# MIMXRT1064 register map
Vendor: nxp.com; File version: 1.0
CPU: CM7 r0p1, little endian, MPU, FPU, VTOR, 4 interrupt priority bits
Registers are 32-bit, read-write, reset 0x0 unless marked. A register's access mark holds for its fields unless they carry their own. Offsets are from the block's base; [hi:lo] are bit positions; {n}, {i} and the like mark numbered series; 'fields as' and 'values as' point back to an identical list.

## USB1 — USB
Base 0x402E0000; register names take the prefix USB_
Same registers: USB2 0x402E0200
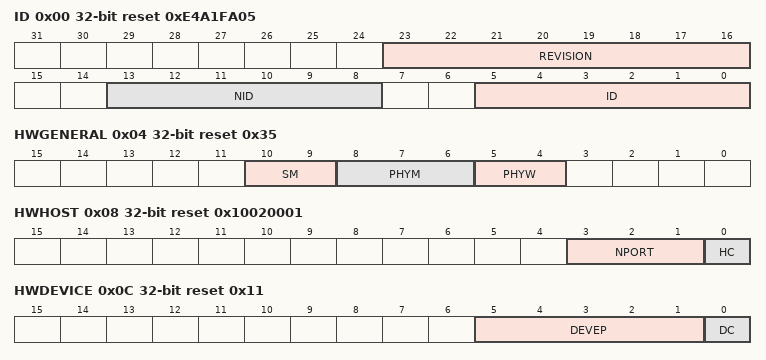
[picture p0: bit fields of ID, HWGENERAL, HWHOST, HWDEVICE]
0x00 ID ro reset 0xE4A1FA05 — Identification register
  [23:16] REVISION — Revision number of the controller core.
  [13:8] NID — Complement version of ID
  [5:0] ID — Configuration number
0x04 HWGENERAL ro reset 0x35 — Hardware General
  [10:9] SM — Serial interface mode capability
    0=No Serial Engine, always use parallel signalling; 1=Serial Engine present, always use serial signalling for FS/LS; 2=Software programmable - Reset to use parallel signalling for FS/LS; 3=Software programmable - Reset to use serial signalling for FS/LS
  [8:6] PHYM — Transciever type
    0=UTMI/UMTI+; 1=ULPI DDR; 2=ULPI; 3=Serial Only; 4=Software programmable - reset to UTMI/UTMI+; 5=Software programmable - reset to ULPI DDR; 6=Software programmable - reset to ULPI; 7=Software programmable - reset to Serial
  [5:4] PHYW — Data width of the transciever connected to the controller core. PHYW bit reset value is
    0=8 bit wide data bus Software non-programmable; 1=16 bit wide data bus Software non-programmable; 2=Reset to 8 bit wide data bus Software programmable; 3=Reset to 16 bit wide data bus Software programmable
0x08 HWHOST ro reset 0x10020001 — Host Hardware Parameters
  [3:1] NPORT — The Nmber of downstream ports supported by the host controller is (NPORT+1)
  [0] HC — Host Capable. Indicating whether host operation mode is supported or not.
    0=Not supported; 1=Supported
0x0C HWDEVICE ro reset 0x11 — Device Hardware Parameters
  [5:1] DEVEP — Device Endpoint Number
  [0] DC — Device Capable. Indicating whether device operation mode is supported or not.
    0=Not supported; 1=Supported
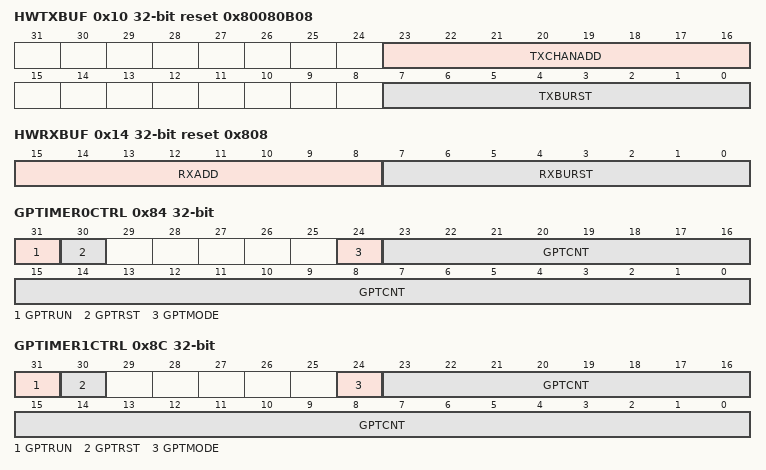
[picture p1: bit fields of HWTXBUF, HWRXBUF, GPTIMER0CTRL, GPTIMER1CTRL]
0x10 HWTXBUF ro reset 0x80080B08 — TX Buffer Hardware Parameters
  [23:16] TXCHANADD — TX FIFO Buffer size is: (2^TXCHANADD) * 4 Bytes
  [7:0] TXBURST — Default burst size for memory to TX buffer transfer
0x14 HWRXBUF ro reset 0x808 — RX Buffer Hardware Parameters
  [15:8] RXADD — Buffer total size for all receive endpoints is (2^RXADD)
  [7:0] RXBURST — Default burst size for memory to RX buffer transfer
0x80 GPTIMER0LD — General Purpose Timer #0 Load
  [23:0] GPTLD — General Purpose Timer Load Value These bit fields are loaded to GPTCNT bits when GPTRST bit is set '1b'
0x84 GPTIMER0CTRL — General Purpose Timer #0 Controller
  [31] GPTRUN — General Purpose Timer Run GPTCNT bits are not effected when setting or clearing this bit.
    0=Stop counting; 1=Run
  [30] GPTRST — General Purpose Timer Reset
    0=No action; 1=Load counter value from GPTLD bits in n_GPTIMER0LD
  [24] GPTMODE — General Purpose Timer Mode In one shot mode, the timer will count down to zero, generate an interrupt, and stop until the counter is reset by software; In repeat mode, the timer will count down to zero, generate an interrupt and automatically reload the counter value from GPTLD bits to start again
    0=One Shot Mode; 1=Repeat Mode
  [23:0] GPTCNT — General Purpose Timer Counter. This field is the count value of the countdown timer.
0x88 GPTIMER1LD — General Purpose Timer #1 Load
  fields as GPTIMER0LD
0x8C GPTIMER1CTRL — General Purpose Timer #1 Controller
  [31] GPTRUN — General Purpose Timer Run GPTCNT bits are not effected when setting or clearing this bit.
    0=Stop counting; 1=Run
  [30] GPTRST — General Purpose Timer Reset
    0=No action; 1=Load counter value from GPTLD bits in USB_n_GPTIMER0LD
  [24] GPTMODE — General Purpose Timer Mode In one shot mode, the timer will count down to zero, generate an interrupt, and stop until the counter is reset by software
    0=One Shot Mode; 1=Repeat Mode
  [23:0] GPTCNT — General Purpose Timer Counter. This field is the count value of the countdown timer.
0x90 SBUSCFG reset 0x2 — System Bus Config
  [2:0] AHBBRST — AHB master interface Burst configuration These bits control AHB master transfer type sequence (or priority)
    0=Incremental burst of unspecified length only; 1=INCR4 burst, then single transfer; 2=INCR8 burst, INCR4 burst, then single transfer; 3=INCR16 burst, INCR8 burst, INCR4 burst, then single transfer; 5=INCR4 burst, then incremental burst of unspecified length; 6=INCR8 burst, INCR4 burst, then incremental burst of unspecified length; 7=INCR16 burst, INCR8 burst, INCR4 burst, then incremental burst of unspecified length
0x100 CAPLENGTH 8-bit ro reset 0x40 — Capability Registers Length
  [7:0] CAPLENGTH — These bits are used as an offset to add to register base to find the beginning of the Operational Register
0x102 HCIVERSION 16-bit ro reset 0x100 — Host Controller Interface Version
  [15:0] HCIVERSION — Host Controller Interface Version Number Default value is '10h', which means EHCI rev1.0.
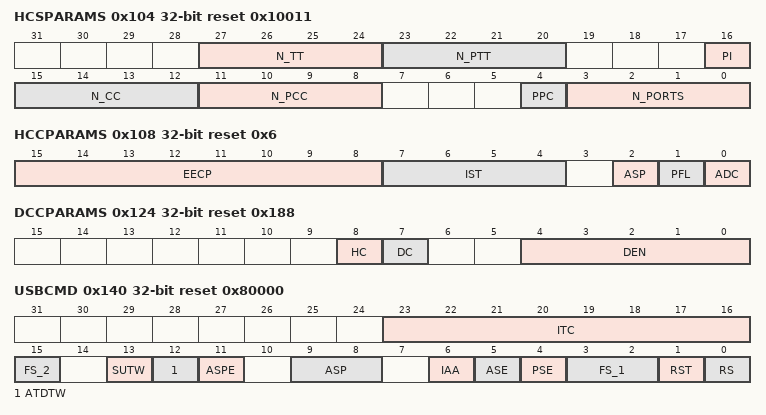
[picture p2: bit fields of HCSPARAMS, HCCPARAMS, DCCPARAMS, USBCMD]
0x104 HCSPARAMS ro reset 0x10011 — Host Controller Structural Parameters
  [27:24] N_TT — Number of Transaction Translators (N_TT)
  [23:20] N_PTT — Number of Ports per Transaction Translator (N_PTT)
  [16] PI — Port Indicators (P INDICATOR) This bit indicates whether the ports support port indicator control
  [15:12] N_CC — Number of Companion Controller (N_CC)
    0=There is no internal Companion Controller and port-ownership hand-off is not supported; 1=There are internal companion controller(s) and port-ownership hand-offs is supported
  [11:8] N_PCC — Number of Ports per Companion Controller This field indicates the number of ports supported per internal Companion Controller
  [4] PPC — Port Power Control This field indicates whether the host controller implementation includes port power control
  [3:0] N_PORTS — Number of downstream ports
0x108 HCCPARAMS ro reset 0x6 — Host Controller Capability Parameters
  [15:8] EECP — EHCI Extended Capabilities Pointer
  [7:4] IST — Isochronous Scheduling Threshold
  [2] ASP — Asynchronous Schedule Park Capability If this bit is set to a one, then the host controller supports the park feature for high-speed queue heads in the Asynchronous Schedule
  [1] PFL — Programmable Frame List Flag If this bit is set to zero, then the system software must use a frame list length of 1024 elements with this host controller
  [0] ADC — 64-bit Addressing Capability This bit is set '0b' in all controller core, no 64-bit addressing capability is supported
0x120 DCIVERSION 16-bit ro reset 0x1 — Device Controller Interface Version
  [15:0] DCIVERSION — Device Controller Interface Version Number Default value is '01h', which means rev0.1.
0x124 DCCPARAMS ro reset 0x188 — Device Controller Capability Parameters
  [8] HC — Host Capable When this bit is 1, this controller is capable of operating as an EHCI compatible USB 2
  [7] DC — Device Capable When this bit is 1, this controller is capable of operating as a USB 2.0 device.
  [4:0] DEN — Device Endpoint Number This field indicates the number of endpoints built into the device controller
0x140 USBCMD reset 0x80000 — USB Command Register
  [23:16] ITC — Interrupt Threshold Control -Read/Write
    0=Immediate (no threshold); 1=1 micro-frame; 2=2 micro-frames; 4=4 micro-frames; 8=8 micro-frames; 16=16 micro-frames; 32=32 micro-frames; 64=64 micro-frames
  [15] FS_2 — See also bits 3-2 Frame List Size - (Read/Write or Read Only)
    0=1024 elements (4096 bytes) Default value; 1=512 elements (2048 bytes)
  [13] SUTW — Setup TripWire - Read/Write
  [12] ATDTW — Add dTD TripWire - Read/Write
  [11] ASPE — Asynchronous Schedule Park Mode Enable - Read/Write
  [9:8] ASP — Asynchronous Schedule Park Mode Count - Read/Write
  [6] IAA — Interrupt on Async Advance Doorbell - Read/Write
  [5] ASE — Asynchronous Schedule Enable - Read/Write
    0=Do not process the Asynchronous Schedule; 1=Use the ASYNCLISTADDR register to access the Asynchronous Schedule
  [4] PSE — Periodic Schedule Enable- Read/Write
    0=Do not process the Periodic Schedule; 1=Use the PERIODICLISTBASE register to access the Periodic Schedule
  [3:2] FS_1 — See description at bit 15
  [1] RST — Controller Reset (RESET) - Read/Write
  [0] RS — Run/Stop (RS) - Read/Write
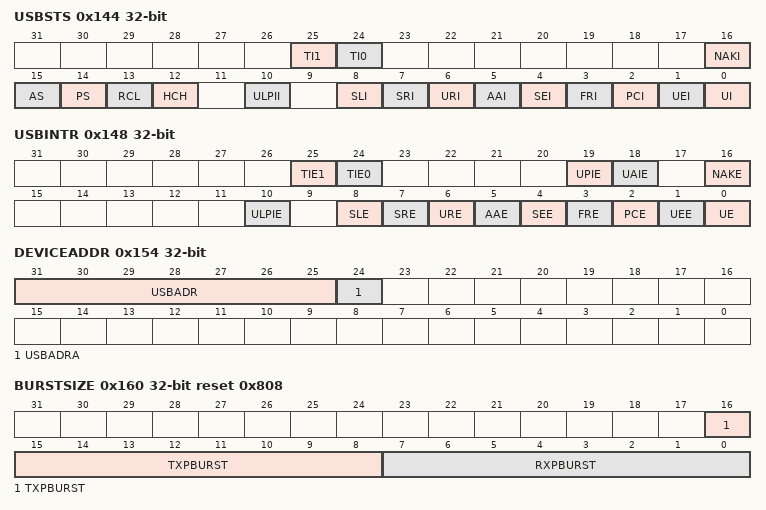
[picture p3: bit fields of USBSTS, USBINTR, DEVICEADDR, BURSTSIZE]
0x144 USBSTS — USB Status Register
  [25] TI1 — General Purpose Timer Interrupt 1(GPTINT1)--R/WC
  [24] TI0 — General Purpose Timer Interrupt 0(GPTINT0)--R/WC
  [16] NAKI ro — NAK Interrupt Bit--RO
  [15] AS — Asynchronous Schedule Status - Read Only
  [14] PS — Periodic Schedule Status - Read Only
  [13] RCL — Reclamation - Read Only
  [12] HCH — HCHaIted - Read Only
  [10] ULPII — ULPI Interrupt - R/WC
  [8] SLI — DCSuspend - R/WC
  [7] SRI — SOF Received - R/WC
  [6] URI — USB Reset Received - R/WC
  [5] AAI — Interrupt on Async Advance - R/WC
  [4] SEI — System Error- R/WC
  [3] FRI — Frame List Rollover - R/WC
  [2] PCI — Port Change Detect - R/WC
  [1] UEI — USB Error Interrupt (USBERRINT) - R/WC
  [0] UI — USB Interrupt (USBINT) - R/WC
0x148 USBINTR — Interrupt Enable Register
  [25] TIE1 — General Purpose Timer #1 Interrupt Enable When this bit is one and the TI1 bit in n_USBSTS register is a one the controller will issue an interrupt
  [24] TIE0 — General Purpose Timer #0 Interrupt Enable When this bit is one and the TI0 bit in n_USBSTS register is a one the controller will issue an interrupt
  [19] UPIE — USB Host Periodic Interrupt Enable When this bit is one, and the UPI bit in the n_USBSTS register is one, host controller will issue an interrupt at the next interrupt threshold
  [18] UAIE — USB Host Asynchronous Interrupt Enable When this bit is one, and the UAI bit in the n_USBSTS register is one, host controller will issue an interrupt at the next interrupt threshold
  [16] NAKE — NAK Interrupt Enable When this bit is one and the NAKI bit in n_USBSTS register is a one the controller will issue an interrupt
  [10] ULPIE — ULPI Interrupt Enable When this bit is one and the UPLII bit in n_USBSTS register is a one the controller will issue an interrupt
  [8] SLE — Sleep Interrupt Enable When this bit is one and the SLI bit in n_n_USBSTS register is a one the controller will issue an interrupt
  [7] SRE — SOF Received Interrupt Enable When this bit is one and the SRI bit in n_USBSTS register is a one the controller will issue an interrupt
  [6] URE — USB Reset Interrupt Enable When this bit is one and the URI bit in n_USBSTS register is a one the controller will issue an interrupt
  [5] AAE — Async Advance Interrupt Enable When this bit is one and the AAI bit in n_USBSTS register is a one the controller will issue an interrupt
  [4] SEE — System Error Interrupt Enable When this bit is one and the SEI bit in n_USBSTS register is a one the controller will issue an interrupt
  [3] FRE — Frame List Rollover Interrupt Enable When this bit is one and the FRI bit in n_USBSTS register is a one the controller will issue an interrupt
  [2] PCE — Port Change Detect Interrupt Enable When this bit is one and the PCI bit in n_USBSTS register is a one the controller will issue an interrupt
  [1] UEE — USB Error Interrupt Enable When this bit is one and the UEI bit in n_USBSTS register is a one the controller will issue an interrupt
  [0] UE — USB Interrupt Enable When this bit is one and the UI bit in n_USBSTS register is a one the controller will issue an interrupt
0x14C FRINDEX — USB Frame Index
  [13:0] FRINDEX — Frame Index
    0=(1024) 12; 1=(512) 11; 2=(256) 10; 3=(128) 9; 4=(64) 8; 5=(32) 7; 6=(16) 6; 7=(8) 5
0x154 DEVICEADDR (DEVICEADDR_PERIODICLISTBASE view) — Device Address
  [31:25] USBADR — Device Address. These bits correspond to the USB device address
  [24] USBADRA — Device Address Advance
0x154 PERIODICLISTBASE (DEVICEADDR_PERIODICLISTBASE view) — Frame List Base Address
  [31:12] BASEADR — Base Address (Low)
0x158 ASYNCLISTADDR (ASYNCLISTADDR_ENDPTLISTADDR view) — Next Asynch. Address
  [31:5] ASYBASE — Link Pointer Low (LPL)
0x158 ENDPTLISTADDR (ASYNCLISTADDR_ENDPTLISTADDR view) — Endpoint List Address
  [31:11] EPBASE — Endpoint List Pointer(Low)
0x160 BURSTSIZE reset 0x808 — Programmable Burst Size
  [16:8] TXPBURST — Programmable TX Burst Size
  [7:0] RXPBURST — Programmable RX Burst Size
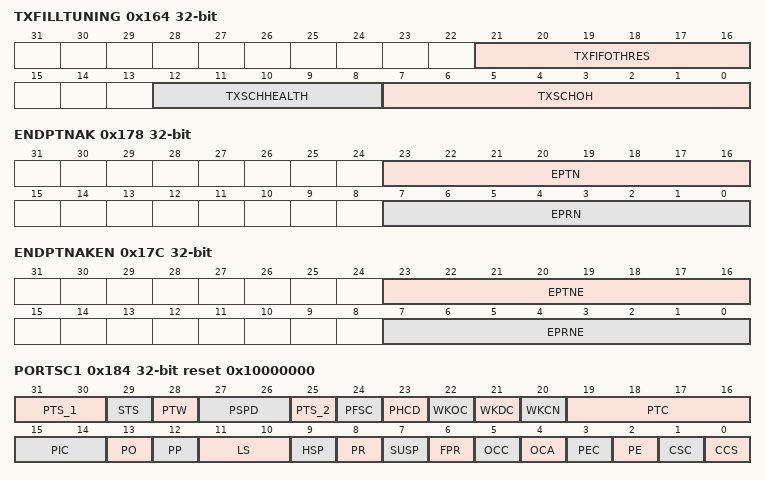
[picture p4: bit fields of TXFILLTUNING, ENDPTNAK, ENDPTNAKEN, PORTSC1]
0x164 TXFILLTUNING — TX FIFO Fill Tuning
  [21:16] TXFIFOTHRES — FIFO Burst Threshold
  [12:8] TXSCHHEALTH — Scheduler Health Counter
  [7:0] TXSCHOH — Scheduler Overhead
0x178 ENDPTNAK — Endpoint NAK
  [23:16] EPTN — TX Endpoint NAK - R/WC
  [7:0] EPRN — RX Endpoint NAK - R/WC
0x17C ENDPTNAKEN — Endpoint NAK Enable
  [23:16] EPTNE — TX Endpoint NAK Enable - R/W
  [7:0] EPRNE — RX Endpoint NAK Enable - R/W
0x180 CONFIGFLAG ro reset 0x1 — Configure Flag Register
  [0] CF — Configure Flag Host software sets this bit as the last action in its process of configuring the Host Controller
    0=Port routing control logic default-routes each port to an implementation dependent classic host controller; 1=Port routing control logic default-routes all ports to this host controller
0x184 PORTSC1 reset 0x10000000 — Port Status & Control
  [31:30] PTS_1 — All USB port interface modes are listed in this field description, but not all are supported
  [29] STS — Serial Transceiver Select 1 Serial Interface Engine is selected 0 Parallel Interface signals is selected Serial Interface Engine can be used in combination with UTMI+/ULPI physical interface to provide FS/LS signaling instead of the parallel interface signals
  [28] PTW — Parallel Transceiver Width This bit has no effect if serial interface engine is used
    0=Select the 8-bit UTMI interface [60MHz]; 1=Select the 16-bit UTMI interface [30MHz]
  [27:26] PSPD — Port Speed - Read Only. This register field indicates the speed at which the port is operating.
    0=Full Speed; 1=Low Speed; 2=High Speed; 3=Undefined
  [25] PTS_2 — See description at bits 31-30
  [24] PFSC — Port Force Full Speed Connect - Read/Write
    0=Normal operation; 1=Forced to full speed
  [23] PHCD — PHY Low Power Suspend - Clock Disable (PLPSCD) - Read/Write
    0=Enable PHY clock; 1=Disable PHY clock
  [22] WKOC — Wake on Over-current Enable (WKOC_E) - Read/Write
  [21] WKDC — Wake on Disconnect Enable (WKDSCNNT_E) - Read/Write
  [20] WKCN — Wake on Connect Enable (WKCNNT_E) - Read/Write
  [19:16] PTC — Port Test Control - Read/Write
    0=TEST_MODE_DISABLE; 1=J_STATE; 2=K_STATE; 3=SE0 (host) / NAK (device); 4=Packet; 5=FORCE_ENABLE_HS; 6=FORCE_ENABLE_FS; 7=FORCE_ENABLE_LS
  [15:14] PIC — Port Indicator Control - Read/Write
    0=Port indicators are off; 1=Amber; 2=Green; 3=Undefined
  [13] PO — Port Owner-Read/Write
  [12] PP — Port Power (PP)-Read/Write or Read Only
  [11:10] LS — Line Status-Read Only
    0=SE0; 1=K-state; 2=J-state; 3=Undefined
  [9] HSP ro — High-Speed Port - Read Only
  [8] PR — Port Reset - Read/Write or Read Only
  [7] SUSP — Suspend - Read/Write or Read Only
  [6] FPR — Force Port Resume -Read/Write
  [5] OCC — Over-current Change-R/WC
  [4] OCA ro — Over-current Active-Read Only
    0=This port does not have an over-current condition; 1=This port currently has an over-current condition
  [3] PEC — Port Enable/Disable Change-R/WC
  [2] PE — Port Enabled/Disabled-Read/Write
  [1] CSC — Connect Status Change-R/WC
  [0] CCS ro — Current Connect Status-Read Only
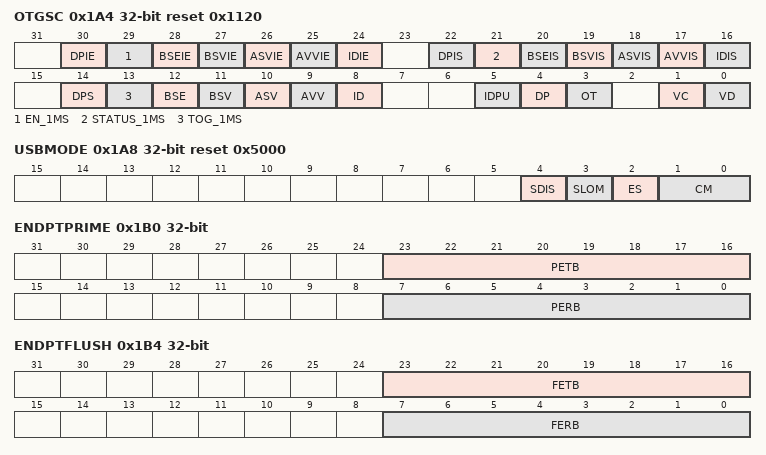
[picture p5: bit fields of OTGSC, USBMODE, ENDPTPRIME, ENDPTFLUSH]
0x1A4 OTGSC reset 0x1120 — On-The-Go Status & control
  [30] DPIE — Data Pulse Interrupt Enable
  [29] EN_1MS — 1 millisecond timer Interrupt Enable - Read/Write
  [28] BSEIE — B Session End Interrupt Enable - Read/Write. Setting this bit enables the B session end interrupt.
  [27] BSVIE — B Session Valid Interrupt Enable - Read/Write
  [26] ASVIE — A Session Valid Interrupt Enable - Read/Write
  [25] AVVIE — A VBus Valid Interrupt Enable - Read/Write. Setting this bit enables the A VBus valid interrupt.
  [24] IDIE — USB ID Interrupt Enable - Read/Write. Setting this bit enables the USB ID interrupt.
  [22] DPIS — Data Pulse Interrupt Status - Read/Write to Clear
  [21] STATUS_1MS — 1 millisecond timer Interrupt Status - Read/Write to Clear
  [20] BSEIS — B Session End Interrupt Status - Read/Write to Clear
  [19] BSVIS — B Session Valid Interrupt Status - Read/Write to Clear
  [18] ASVIS — A Session Valid Interrupt Status - Read/Write to Clear
  [17] AVVIS — A VBus Valid Interrupt Status - Read/Write to Clear
  [16] IDIS — USB ID Interrupt Status - Read/Write
  [14] DPS ro — Data Bus Pulsing Status - Read Only
  [13] TOG_1MS ro — 1 millisecond timer toggle - Read Only. This bit toggles once per millisecond.
  [12] BSE ro — B Session End - Read Only. Indicates VBus is below the B session end threshold.
  [11] BSV ro — B Session Valid - Read Only. Indicates VBus is above the B session valid threshold.
  [10] ASV ro — A Session Valid - Read Only. Indicates VBus is above the A session valid threshold.
  [9] AVV ro — A VBus Valid - Read Only. Indicates VBus is above the A VBus valid threshold.
  [8] ID ro — USB ID - Read Only. 0 = A device, 1 = B device
  [5] IDPU — ID Pullup - Read/Write This bit provide control over the ID pull-up resistor; 0 = off, 1 = on [default]
  [4] DP — Data Pulsing - Read/Write
  [3] OT — OTG Termination - Read/Write
  [1] VC — VBUS Charge - Read/Write
  [0] VD — VBUS_Discharge - Read/Write. Setting this bit causes VBus to discharge through a resistor.
0x1A8 USBMODE reset 0x5000 — USB Device Mode
  [4] SDIS — Stream Disable Mode
  [3] SLOM — Setup Lockout Mode
    0=Setup Lockouts On (default);; 1=Setup Lockouts Off (DCD requires use of Setup Data Buffer Tripwire in USBCMDUSB Command Register 
  [2] ES — Endian Select - Read/Write
    0=Little Endian [Default]; 1=Big Endian
  [1:0] CM — Controller Mode - R/WO
    0=Idle [Default for combination host/device]; 2=Device Controller [Default for device only controller]; 3=Host Controller [Default for host only controller]
0x1AC ENDPTSETUPSTAT — Endpoint Setup Status
  [15:0] ENDPTSETUPSTAT — Setup Endpoint Status
0x1B0 ENDPTPRIME — Endpoint Prime
  [23:16] PETB — Prime Endpoint Transmit Buffer - R/WS
  [7:0] PERB — Prime Endpoint Receive Buffer - R/WS
0x1B4 ENDPTFLUSH — Endpoint Flush
  [23:16] FETB — Flush Endpoint Transmit Buffer - R/WS
  [7:0] FERB — Flush Endpoint Receive Buffer - R/WS
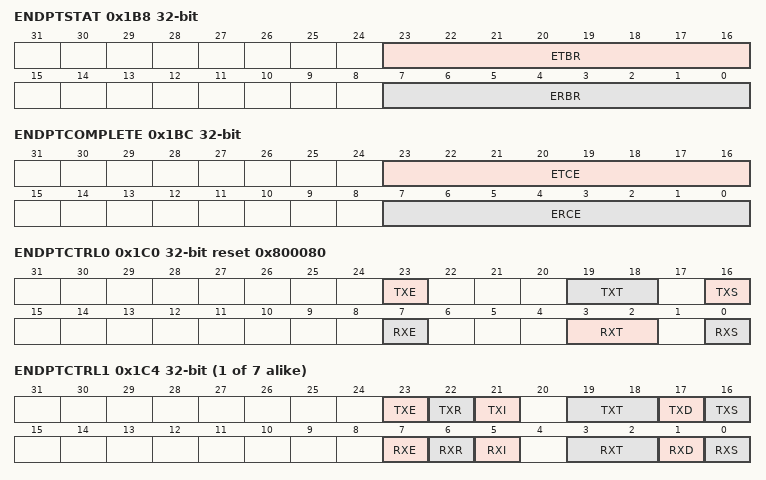
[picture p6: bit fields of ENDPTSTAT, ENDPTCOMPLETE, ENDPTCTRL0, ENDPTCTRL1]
0x1B8 ENDPTSTAT ro — Endpoint Status
  [23:16] ETBR — Endpoint Transmit Buffer Ready -- Read Only
  [7:0] ERBR — Endpoint Receive Buffer Ready -- Read Only
0x1BC ENDPTCOMPLETE — Endpoint Complete
  [23:16] ETCE — Endpoint Transmit Complete Event - R/WC
  [7:0] ERCE — Endpoint Receive Complete Event - RW/C
0x1C0 ENDPTCTRL0 reset 0x800080 — Endpoint Control0
  [23] TXE — TX Endpoint Enable 1 Enabled Endpoint0 is always enabled.
  [19:18] TXT — TX Endpoint Type - Read/Write 00 - Control Endpoint0 is fixed as a Control End Point.
  [16] TXS — TX Endpoint Stall - Read/Write 0 End Point OK [Default] 1 End Point Stalled Software can write a one to this bit to force the endpoint to return a STALL handshake to the Host
  [7] RXE — RX Endpoint Enable 1 Enabled Endpoint0 is always enabled.
  [3:2] RXT — RX Endpoint Type - Read/Write 00 Control Endpoint0 is fixed as a Control End Point.
  [0] RXS — RX Endpoint Stall - Read/Write 0 End Point OK
{0x1C0+4i} ENDPTCTRL{i} (i=1..7) — Endpoint Control {i}
  [23] TXE — TX Endpoint Enable 0 Disabled [Default] 1 Enabled An Endpoint should be enabled only after it has been configured
  [22] TXR — TX Data Toggle Reset (WS) Write 1 - Reset PID Sequence Whenever a configuration event is received for this Endpoint, software must write a one to this bit in order to synchronize the data PID's between the Host and device
  [21] TXI — TX Data Toggle Inhibit 0 PID Sequencing Enabled
  [19:18] TXT — TX Endpoint Type - Read/Write 00 Control 01 Isochronous 10 Bulk 11 Interrupt
  [17] TXD — TX Endpoint Data Source - Read/Write 0 Dual Port Memory Buffer/DMA Engine [DEFAULT] Should always be written as 0
  [16] TXS — TX Endpoint Stall - Read/Write 0 End Point OK 1 End Point Stalled This bit will be cleared automatically upon receipt of a SETUP request if this Endpoint is configured as a Control Endpoint and this bit will continue to be cleared by hardware until the associated ENDPTSETUPSTAT bit is cleared
  [7] RXE — RX Endpoint Enable 0 Disabled [Default] 1 Enabled An Endpoint should be enabled only after it has been configured
  [6] RXR — RX Data Toggle Reset (WS) Write 1 - Reset PID Sequence Whenever a configuration event is received for this Endpoint, software must write a one to this bit in order to synchronize the data PID's between the host and device
  [5] RXI — RX Data Toggle Inhibit 0 Disabled [Default] 1 Enabled This bit is only used for test and should always be written as zero
  [3:2] RXT — RX Endpoint Type - Read/Write 00 Control 01 Isochronous 10 Bulk 11 Interrupt
  [1] RXD — RX Endpoint Data Sink - Read/Write 0 Dual Port Memory Buffer/DMA Engine [Default] Should always be written as zero
  [0] RXS — RX Endpoint Stall - Read/Write 0 End Point OK
